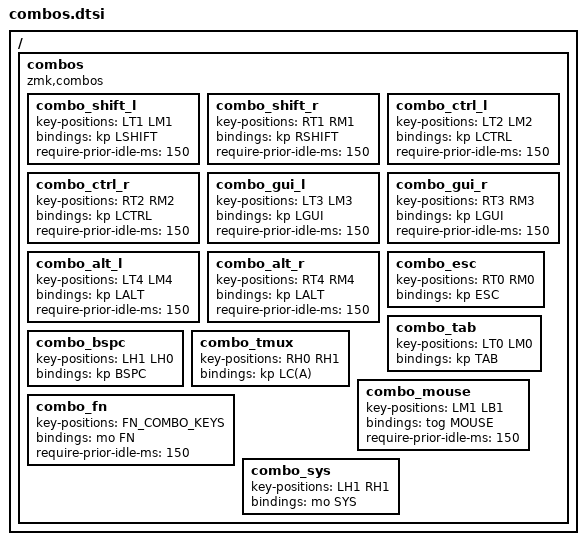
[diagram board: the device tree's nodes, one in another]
/*
 * Unified combo definitions — shared by all board sizes.
 * Requires key_positions.h to be included first (via base_layers.dtsi).
 *
 * Position names follow urob/zmk-helpers convention: 0 = inner (index side),
 * 4 = outer (pinky side). Thumbs: H0 = innermost, H1 = outer.
 *
 * To add a combo that only exists on some boards, guard it with a position
 * that key_positions.h defines only for those boards:
 *
 *   #if defined(LB4)          // BOARD_34, 36, 42 — not BOARD_30
 *   combo_foo { key-positions = <LB4 LM4>; bindings = <&foo>; };
 *   #endif
 *
 *   #if defined(LH2)          // BOARD_36, 42 — not BOARD_30 or BOARD_34
 *   combo_bar { key-positions = <LH2 LH1>; bindings = <&bar>; };
 *   #endif
 *
 *   #if defined(LT5)          // BOARD_42 only
 *   combo_baz { key-positions = <LT5 LM4>; bindings = <&baz>; };
 *   #endif
 */

/ {
    combos {
        compatible = "zmk,combos";

        /* ── Modifier combos (vertical same-column, top+home) ───────────── */
        combo_shift_l {
            key-positions = <LT1 LM1>;
            bindings = <&kp LSHIFT>;
            require-prior-idle-ms = <150>;
        };
        combo_shift_r {
            key-positions = <RT1 RM1>;
            bindings = <&kp RSHIFT>;
            require-prior-idle-ms = <150>;
        };
        combo_ctrl_l {
            key-positions = <LT2 LM2>;
            bindings = <&kp LCTRL>;
            require-prior-idle-ms = <150>;
        };
        combo_ctrl_r {
            key-positions = <RT2 RM2>;
            bindings = <&kp LCTRL>;
            require-prior-idle-ms = <150>;
        };
        combo_gui_l {
            key-positions = <LT3 LM3>;
            bindings = <&kp LGUI>;
            require-prior-idle-ms = <150>;
        };
        combo_gui_r {
            key-positions = <RT3 RM3>;
            bindings = <&kp LGUI>;
            require-prior-idle-ms = <150>;
        };
        combo_alt_l {
            key-positions = <LT4 LM4>;
            bindings = <&kp LALT>;
            require-prior-idle-ms = <150>;
        };
        combo_alt_r {
            key-positions = <RT4 RM4>;
            bindings = <&kp LALT>;
            require-prior-idle-ms = <150>;
        };

        /* ── Action combos ───────────────────────────────────────────────── */
        combo_esc {
            key-positions = <RT0 RM0>;
            bindings = <&kp ESC>;
        };
        combo_tab {
            key-positions = <LT0 LM0>;
            bindings = <&kp TAB>;
        };
        combo_bspc {
            key-positions = <LH1 LH0>;
            bindings = <&kp BSPC>;
        };
        combo_tmux {
            key-positions = <RH0 RH1>;
            bindings = <&kp LC(A)>;
        };

        /* ── Layer combos ────────────────────────────────────────────────── */
        combo_mouse {
            key-positions = <LM1 LB1>;
            bindings = <&tog MOUSE>;
            require-prior-idle-ms = <150>;
        };
        combo_fn {
            key-positions = <FN_COMBO_KEYS>;
            bindings = <&mo FN>;
            require-prior-idle-ms = <150>;
        };
        combo_sys {
            key-positions = <LH1 RH1>;
            bindings = <&mo SYS>;
        };
    };
};
